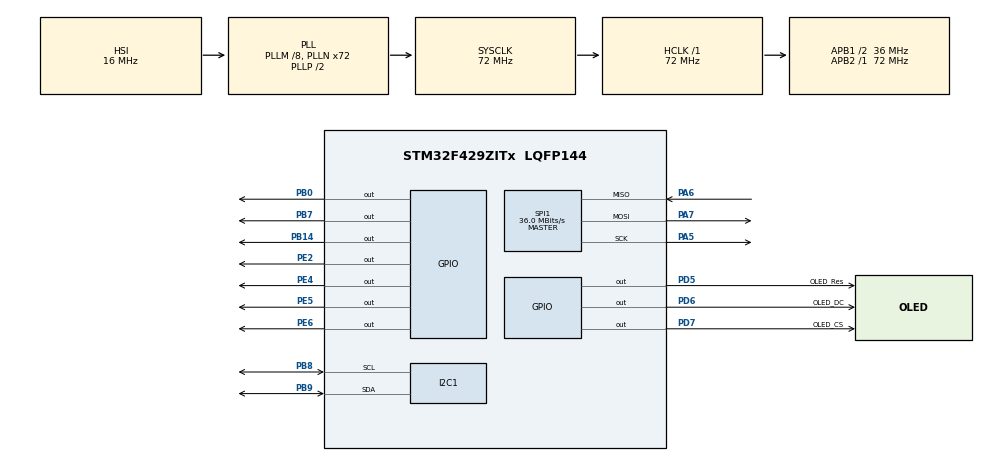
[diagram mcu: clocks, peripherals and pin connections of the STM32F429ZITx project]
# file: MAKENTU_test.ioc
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I2C1.I2C_Mode=I2C_Fast
Mcu.Family=STM32F4
Mcu.Name=STM32F429ZITx
Mcu.Package=LQFP144
NVIC.PriorityGroup=NVIC_PRIORITYGROUP_4
PA5.Mode=Full_Duplex_Master
PA5.Signal=SPI1_SCK
PA6.Mode=Full_Duplex_Master
PA6.Signal=SPI1_MISO
PA7.Mode=Full_Duplex_Master
PA7.Signal=SPI1_MOSI
PB0.Signal=GPIO_Output
PB14.Signal=GPIO_Output
PB7.Signal=GPIO_Output
PB8.Mode=I2C
PB8.Signal=I2C1_SCL
PB9.Mode=I2C
PB9.Signal=I2C1_SDA
PD5.GPIO_Label=OLED_Res
PD5.Signal=GPIO_Output
PD6.GPIO_Label=OLED_DC
PD6.GPIO_Speed=GPIO_SPEED_FREQ_VERY_HIGH
PD6.Signal=GPIO_Output
PD7.GPIO_Label=OLED_CS
PD7.GPIO_Speed=GPIO_SPEED_FREQ_VERY_HIGH
PD7.Signal=GPIO_Output
PE2.Signal=GPIO_Output
PE4.Signal=GPIO_Output
PE5.Signal=GPIO_Output
PE6.Signal=GPIO_Output
PH0/OSC_IN.Mode=HSE-External-Oscillator
PH0/OSC_IN.Signal=RCC_OSC_IN
PH1/OSC_OUT.Mode=HSE-External-Oscillator
PH1/OSC_OUT.Signal=RCC_OSC_OUT
ProjectManager.HeapSize=0x200
ProjectManager.StackSize=0x400
ProjectManager.TargetToolchain=STM32CubeIDE
RCC.48MHZClocksFreq_Value=36000000
RCC.AHBFreq_Value=72000000
RCC.APB1CLKDivider=RCC_HCLK_DIV2
RCC.APB1Freq_Value=36000000
RCC.APB1TimFreq_Value=72000000
RCC.APB2Freq_Value=72000000
RCC.APB2TimFreq_Value=72000000
RCC.CortexFreq_Value=72000000
RCC.HCLKFreq_Value=72000000
RCC.HSE_VALUE=25000000
RCC.HSI_VALUE=16000000
RCC.LSE_VALUE=32768
RCC.PLLM=8
RCC.PLLN=72
RCC.SYSCLKFreq_VALUE=72000000
RCC.SYSCLKSource=RCC_SYSCLKSOURCE_PLLCLK
RCC.VCOOutputFreq_Value=144000000
SPI1.CalculateBaudRate=36.0 MBits/s
SPI1.Direction=SPI_DIRECTION_2LINES
SPI1.Mode=SPI_MODE_MASTER
SPI1.VirtualType=VM_MASTER
TIM2.Prescaler=71
VP_TIM2_VS_ClockSourceINT.Mode=Internal
board=custom

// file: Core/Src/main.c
/* USER CODE BEGIN Header */
/**
  ******************************************************************************
  * @file           : main.c
  * @brief          : Main program body
  ******************************************************************************
  * @attention
  *
  * Copyright (c) 2024 STMicroelectronics.
  * All rights reserved.
  *
  * This software is licensed under terms that can be found in the LICENSE file
  * in the root directory of this software component.
  * If no LICENSE file comes with this software, it is provided AS-IS.
  *
  ******************************************************************************
  */
/* USER CODE END Header */
#include "main.h"
#include "i2c.h"
#include "spi.h"
#include "tim.h"
#include "gpio.h"

/* USER CODE BEGIN Includes */
#include "stm32f429xx.h"
#include "pca9955.h"
#include "ssd1306.h"
#include "ssd1306_tests.h"
#include "ssd1306_fonts.h"
#include "stepmotor.h"
/* USER CODE END Includes */

void SystemClock_Config(void);

int main(void)
{

  /* MCU Configuration--------------------------------------------------------*/

  /* Reset of all peripherals, Initializes the Flash interface and the Systick. */
  HAL_Init();

  /* Configure the system clock */
  SystemClock_Config();

  /* Initialize all configured peripherals */
  MX_GPIO_Init();
  MX_I2C1_Init();
  MX_SPI1_Init();
  MX_TIM2_Init();
  /* USER CODE BEGIN 2 */
  ssd1306_Init();
  HAL_TIM_Base_Start(&htim2);
//  char mystr[] = {"Hello World"};
//  ssd1306_Fill(White);
  // ssd1306_SetCursor(5,10);
  // ssd1306_WriteString(mystr, Font_11x18 , White);
  // ssd1306_DrawLogo();
//   ssd1306_TestAll();
  // ssd1306_UpdateScreen();
  /* USER CODE END 2 */

  /* Infinite loop */
  /* USER CODE BEGIN WHILE */
//  int delaytime = 300;
//  PCA9955_InitALL(&hi2c1);
//  PCA9955_ClearAll(&hi2c1);
  while (1)
  {
    // RGB_Blink(&hi2c1, delaytime);
    // Rapid_Blink(&hi2c1);
    // BreathRGB_Show(&hi2c1);
    // HAL_Delay(delaytime);
    // stepCV(70, 1000, &htim2);  // 256 half revolution
    // HAL_Delay(1000);
    // stepCCV(70, 1000, &htim2); // 128 quarter revolution
    // HAL_Delay(1000);
    ssd1306_TestAll();
    /* USER CODE END WHILE */

  }
}

void SystemClock_Config(void)
{
  RCC_OscInitTypeDef RCC_OscInitStruct = {0};
  RCC_ClkInitTypeDef RCC_ClkInitStruct = {0};

  /** Configure the main internal regulator output voltage
  */
  __HAL_RCC_PWR_CLK_ENABLE();
  __HAL_PWR_VOLTAGESCALING_CONFIG(PWR_REGULATOR_VOLTAGE_SCALE3);

  /** Initializes the RCC Oscillators according to the specified parameters
  * in the RCC_OscInitTypeDef structure.
  */
  RCC_OscInitStruct.OscillatorType = RCC_OSCILLATORTYPE_HSI;
  RCC_OscInitStruct.HSIState = RCC_HSI_ON;
  RCC_OscInitStruct.HSICalibrationValue = RCC_HSICALIBRATION_DEFAULT;
  RCC_OscInitStruct.PLL.PLLState = RCC_PLL_ON;
  RCC_OscInitStruct.PLL.PLLSource = RCC_PLLSOURCE_HSI;
  RCC_OscInitStruct.PLL.PLLM = 8;
  RCC_OscInitStruct.PLL.PLLN = 72;
  RCC_OscInitStruct.PLL.PLLP = RCC_PLLP_DIV2;
  RCC_OscInitStruct.PLL.PLLQ = 4;
  if (HAL_RCC_OscConfig(&RCC_OscInitStruct) != HAL_OK)
  {
    Error_Handler();
  }

  /** Initializes the CPU, AHB and APB buses clocks
  */
  RCC_ClkInitStruct.ClockType = RCC_CLOCKTYPE_HCLK|RCC_CLOCKTYPE_SYSCLK
                              |RCC_CLOCKTYPE_PCLK1|RCC_CLOCKTYPE_PCLK2;
  RCC_ClkInitStruct.SYSCLKSource = RCC_SYSCLKSOURCE_PLLCLK;
  RCC_ClkInitStruct.AHBCLKDivider = RCC_SYSCLK_DIV1;
  RCC_ClkInitStruct.APB1CLKDivider = RCC_HCLK_DIV2;
  RCC_ClkInitStruct.APB2CLKDivider = RCC_HCLK_DIV1;

  if (HAL_RCC_ClockConfig(&RCC_ClkInitStruct, FLASH_LATENCY_2) != HAL_OK)
  {
    Error_Handler();
  }
}

void Error_Handler(void)
{
  __disable_irq();
  while (1)
  {
  }
}
